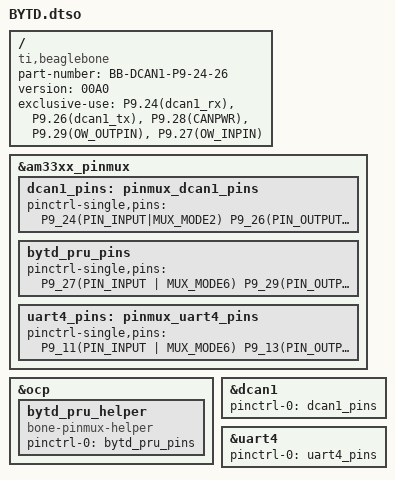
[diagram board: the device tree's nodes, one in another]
/dts-v1/;
/plugin/;

#include <dt-bindings/pinctrl/am33xx.h>
#include <dt-bindings/board/am335x-bone-pins.h>
#include <dt-bindings/gpio/gpio.h>

/ {
    compatible = "ti,beaglebone", "ti,am33xx";
    part-number = "BB-DCAN1-P9-24-26";
    version = "00A0";

    /* document the pins you're reserving */
    exclusive-use =
        "P9.24(dcan1_rx)",
        "P9.26(dcan1_tx)",
        "P9.28(CANPWR)",
        "P9.29(OW_OUTPIN)",
        "P9.27(OW_INPIN)";

/*
git clone --branch v5.10.x-ti https://github.com/beagleboard/BeagleBoard-DeviceTrees.git

    # CANRX P9.24 dcan1_rx
    # CANTX P9.26 dcan1_tx
    # CANPWR P9.28 gpio3_17
    
    # OWIN P9.27 pru0_r31_in5
    # OWOUT P9.29 pru0_r30_out1
    # OWSPWR P9.31 pru0_r30_out0
    # PUMPA P9.25
    # IMPELM p9.23
    # IMPVM p9.21
    
    # OTIN pru0_in14 P8_16
    # OTOUT pru0_out14 P8_12
*/
    fragment@0 {
        target = <&am33xx_pinmux>;
        __overlay__ {
            dcan1_pins: pinmux_dcan1_pins {
                pinctrl-single,pins = <
                    P9_24(PIN_INPUT|MUX_MODE2)
                    P9_26(PIN_OUTPUT|MUX_MODE2)
                >;
            };
            bytd_pru_pins: bytd_pru_pins {
                pinctrl-single,pins = <
                    P9_27(PIN_INPUT | MUX_MODE6)
                    P9_29(PIN_OUTPUT | MUX_MODE5)
                    P9_31(PIN_OUTPUT | MUX_MODE5)
                    P8_16(PIN_INPUT | MUX_MODE6)
                    P8_12(PIN_OUTPUT | MUX_MODE6)
                >;
            };
            uart4_pins: pinmux_uart4_pins {
                /*compatible = "pinctrl-single";*/
                pinctrl-single,pins = <
                    P9_11(PIN_INPUT | MUX_MODE6)
                    P9_13(PIN_OUTPUT | MUX_MODE6)
                >;
            };
        };
    };

    fragment@1 {
        target = <&ocp>;
        __overlay__ {
            bytd_pru_helper {
                compatible = "bone-pinmux-helper";
                pinctrl-names = "default";
                pinctrl-0 = <&bytd_pru_pins>;
            };
        };
    };

    fragment@2 {
        target = <&dcan1>;
        __overlay__ {
            status = "okay";
            pinctrl-names = "default";
            pinctrl-0 = <&dcan1_pins>;
        };
    };

    fragment@3 {
      target = <&uart4>;
        __overlay__ {
            status = "okay";
            pinctrl-names = "default";
            pinctrl-0 = <&uart4_pins>;
        };
    };

    /*
    fragment@4 {
        target = <&pruss>;
        __overlay__ {
            status = "okay";
            firmware-name = "pru1-fw.bin";
            remoteproc1: remoteproc@1 {
                compatible = "ti,pru-rproc";
                status = "okay";
                firmware-name = "pru1-fw.bin";
            };
        };
    };
    */
};
